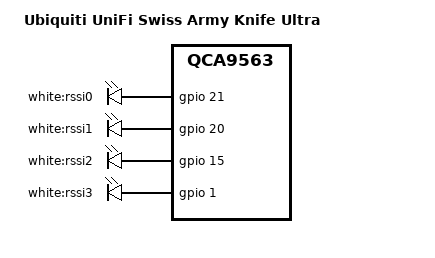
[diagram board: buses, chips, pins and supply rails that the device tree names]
// SPDX-License-Identifier: GPL-2.0-or-later OR MIT

#include "qca9563_ubnt_unifiac-lite.dtsi"

/ {
	compatible = "ubnt,uk-ultra", "qca,qca9563";
	model = "Ubiquiti UniFi Swiss Army Knife Ultra";
};

&leds {
	led-rssi0 {
		label = "white:rssi0";
		gpios = <&gpio 21 GPIO_ACTIVE_HIGH>;
	};

	led-rssi1 {
		label = "white:rssi1";
		gpios = <&gpio 20 GPIO_ACTIVE_HIGH>;
	};

	led-rssi2 {
		label = "white:rssi2";
		gpios = <&gpio 15 GPIO_ACTIVE_HIGH>;
	};

	led-rssi3 {
		label = "white:rssi3";
		gpios = <&gpio 1 GPIO_ACTIVE_HIGH>;
	};
};

/**
 * Antenna selection on GPIO5 and GPIO6
 * High = Internal ; Low = External
 */
